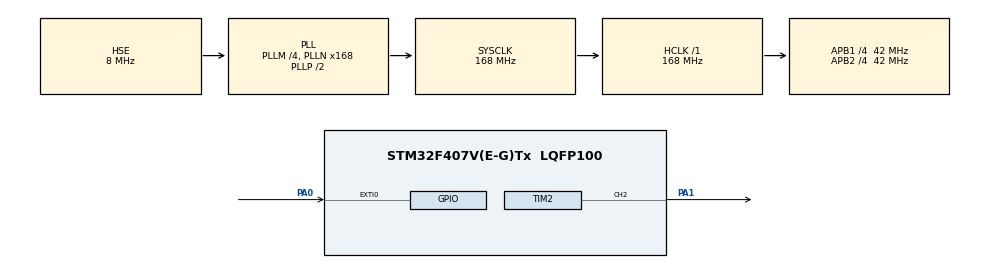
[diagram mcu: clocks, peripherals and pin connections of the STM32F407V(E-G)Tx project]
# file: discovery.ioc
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Mcu.Family=STM32F4
Mcu.Name=STM32F407V(E-G)Tx
Mcu.Package=LQFP100
NVIC.EXTI0_IRQn=true\:0\:0\:false\:false\:true\:true\:true\:true
NVIC.PriorityGroup=NVIC_PRIORITYGROUP_4
NVIC.TIM6_DAC_IRQn=true\:0\:0\:false\:false\:true\:true\:true\:true
PA0-WKUP.Signal=GPXTI0
PA1.Signal=S_TIM2_CH2
PH0-OSC_IN.Mode=HSE-External-Oscillator
PH0-OSC_IN.Signal=RCC_OSC_IN
PH1-OSC_OUT.Mode=HSE-External-Oscillator
PH1-OSC_OUT.Signal=RCC_OSC_OUT
ProjectManager.HeapSize=0x200
ProjectManager.StackSize=0x400
ProjectManager.TargetToolchain=STM32CubeIDE
RCC.48MHZClocksFreq_Value=84000000
RCC.AHBFreq_Value=168000000
RCC.APB1CLKDivider=RCC_HCLK_DIV4
RCC.APB1Freq_Value=42000000
RCC.APB1TimFreq_Value=84000000
RCC.APB2CLKDivider=RCC_HCLK_DIV4
RCC.APB2Freq_Value=42000000
RCC.APB2TimFreq_Value=84000000
RCC.CortexFreq_Value=168000000
RCC.HCLKFreq_Value=168000000
RCC.HSE_VALUE=8000000
RCC.HSI_VALUE=16000000
RCC.LSE_VALUE=32768
RCC.PLLM=4
RCC.PLLN=168
RCC.PLLSourceVirtual=RCC_PLLSOURCE_HSE
RCC.SYSCLKFreq_VALUE=168000000
RCC.SYSCLKSource=RCC_SYSCLKSOURCE_PLLCLK
RCC.VCOOutputFreq_Value=336000000
SH.S_TIM2_CH2.0=TIM2_CH2,PWM Generation2 CH2
TIM2.Channel-PWM\ Generation2\ CH2=TIM_CHANNEL_2
TIM2.Period=9999
TIM2.Prescaler=83
TIM6.AutoReloadPreload=TIM_AUTORELOAD_PRELOAD_ENABLE
TIM6.Period=999
TIM6.Prescaler=83
TIM6.TIM_MasterOutputTrigger=TIM_TRGO_UPDATE
VP_TIM2_VS_ClockSourceINT.Mode=Internal
VP_TIM6_VS_ClockSourceINT.Mode=Enable_Timer
board=custom

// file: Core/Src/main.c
/* USER CODE BEGIN Header */
/**
 ******************************************************************************
 * @file           : main.c
 * @brief          : Main program body
 ******************************************************************************
 * @attention
 *
 * Copyright (c) 2024 STMicroelectronics.
 * All rights reserved.
 *
 * This software is licensed under terms that can be found in the LICENSE file
 * in the root directory of this software component.
 * If no LICENSE file comes with this software, it is provided AS-IS.
 *
 ******************************************************************************
 */
/* USER CODE END Header */
#include "main.h"

/* USER CODE BEGIN Includes */
#include "stdio.h"
#include "string.h"
/* USER CODE END Includes */

TIM_HandleTypeDef htim2;
TIM_HandleTypeDef htim6;

/* USER CODE BEGIN PV */
#define USE_FULL_ASSERT 1
/* USER CODE END PV */

void SystemClock_Config(void);
static void MX_GPIO_Init(void);
static void MX_TIM6_Init(void);
static void MX_TIM2_Init(void);

/* USER CODE BEGIN 0 */
uint8_t counter = 0;
uint32_t tim_counter = 0;

typedef enum {
	INIT = 0, IDLE, BLE_COMMUNICATION, USER_VALID, LOG, LOCK_ERROR
} lock_states_t;

lock_states_t state = INIT;

typedef enum {
	OK = 0, ERR
} result_t;

result_t init(void);
result_t idle(void);
result_t ble_communication(lock_states_t *state);
result_t open_the_lock(void);
result_t error(void);
result_t log_to_flash(void);

/* USER CODE END 0 */

int main(void) {

	/* MCU Configuration--------------------------------------------------------*/

	/* Reset of all peripherals, Initializes the Flash interface and the Systick. */
	HAL_Init();

	/* Configure the system clock */
	SystemClock_Config();

	/* Initialize all configured peripherals */
	MX_GPIO_Init();
	MX_TIM6_Init();
	MX_TIM2_Init();
	/* USER CODE BEGIN 2 */
	HAL_TIM_Base_Start_IT(&htim6);

	HAL_TIM_PWM_Start(&htim2, TIM_CHANNEL_2);
	TIM2->CCR2 = 3333;
	/* USER CODE END 2 */

	/* Infinite loop */
	while (1) {

		/* USER CODE BEGIN 3 */
		switch (state) {

		case INIT:
			if (init() == OK) {
				state = IDLE;
			} else {
				state = LOCK_ERROR;
			}

			break;

		case IDLE:

			char x[3] = "";
			sprintf(x, "%d",5000000);

			idle();
			break;

		case BLE_COMMUNICATION:
			ble_communication(&state);
			break;
		case LOCK_ERROR:
			// show the error to the user
			state = LOG;
			break;

		case LOG:
			// log output to flash memory
			state = IDLE;
			break;

			// ...

		}
	}
	/* USER CODE END 3 */
}

void SystemClock_Config(void) {
	RCC_OscInitTypeDef RCC_OscInitStruct = { 0 };
	RCC_ClkInitTypeDef RCC_ClkInitStruct = { 0 };

	/** Configure the main internal regulator output voltage
	 */
	__HAL_RCC_PWR_CLK_ENABLE();
	__HAL_PWR_VOLTAGESCALING_CONFIG(PWR_REGULATOR_VOLTAGE_SCALE1);

	/** Initializes the RCC Oscillators according to the specified parameters
	 * in the RCC_OscInitTypeDef structure.
	 */
	RCC_OscInitStruct.OscillatorType = RCC_OSCILLATORTYPE_HSE;
	RCC_OscInitStruct.HSEState = RCC_HSE_ON;
	RCC_OscInitStruct.PLL.PLLState = RCC_PLL_ON;
	RCC_OscInitStruct.PLL.PLLSource = RCC_PLLSOURCE_HSE;
	RCC_OscInitStruct.PLL.PLLM = 4;
	RCC_OscInitStruct.PLL.PLLN = 168;
	RCC_OscInitStruct.PLL.PLLP = RCC_PLLP_DIV2;
	RCC_OscInitStruct.PLL.PLLQ = 4;
	if (HAL_RCC_OscConfig(&RCC_OscInitStruct) != HAL_OK) {
		Error_Handler();
	}

	/** Initializes the CPU, AHB and APB buses clocks
	 */
	RCC_ClkInitStruct.ClockType = RCC_CLOCKTYPE_HCLK | RCC_CLOCKTYPE_SYSCLK
			| RCC_CLOCKTYPE_PCLK1 | RCC_CLOCKTYPE_PCLK2;
	RCC_ClkInitStruct.SYSCLKSource = RCC_SYSCLKSOURCE_PLLCLK;
	RCC_ClkInitStruct.AHBCLKDivider = RCC_SYSCLK_DIV1;
	RCC_ClkInitStruct.APB1CLKDivider = RCC_HCLK_DIV4;
	RCC_ClkInitStruct.APB2CLKDivider = RCC_HCLK_DIV4;

	if (HAL_RCC_ClockConfig(&RCC_ClkInitStruct, FLASH_LATENCY_5) != HAL_OK) {
		Error_Handler();
	}
}

static void MX_TIM2_Init(void) {

	TIM_ClockConfigTypeDef sClockSourceConfig = { 0 };
	TIM_MasterConfigTypeDef sMasterConfig = { 0 };
	TIM_OC_InitTypeDef sConfigOC = { 0 };

	htim2.Instance = TIM2;
	htim2.Init.Prescaler = 83;
	htim2.Init.CounterMode = TIM_COUNTERMODE_UP;
	htim2.Init.Period = 9999;
	htim2.Init.ClockDivision = TIM_CLOCKDIVISION_DIV1;
	htim2.Init.AutoReloadPreload = TIM_AUTORELOAD_PRELOAD_DISABLE;
	if (HAL_TIM_Base_Init(&htim2) != HAL_OK) {
		Error_Handler();
	}
	sClockSourceConfig.ClockSource = TIM_CLOCKSOURCE_INTERNAL;
	if (HAL_TIM_ConfigClockSource(&htim2, &sClockSourceConfig) != HAL_OK) {
		Error_Handler();
	}
	if (HAL_TIM_PWM_Init(&htim2) != HAL_OK) {
		Error_Handler();
	}
	sMasterConfig.MasterOutputTrigger = TIM_TRGO_RESET;
	sMasterConfig.MasterSlaveMode = TIM_MASTERSLAVEMODE_DISABLE;
	if (HAL_TIMEx_MasterConfigSynchronization(&htim2, &sMasterConfig)
			!= HAL_OK) {
		Error_Handler();
	}
	sConfigOC.OCMode = TIM_OCMODE_PWM1;
	sConfigOC.Pulse = 0;
	sConfigOC.OCPolarity = TIM_OCPOLARITY_HIGH;
	sConfigOC.OCFastMode = TIM_OCFAST_DISABLE;
	if (HAL_TIM_PWM_ConfigChannel(&htim2, &sConfigOC, TIM_CHANNEL_2)
			!= HAL_OK) {
		Error_Handler();
	}
	HAL_TIM_MspPostInit(&htim2);

}

static void MX_TIM6_Init(void) {

	TIM_MasterConfigTypeDef sMasterConfig = { 0 };

	htim6.Instance = TIM6;
	htim6.Init.Prescaler = 83;
	htim6.Init.CounterMode = TIM_COUNTERMODE_UP;
	htim6.Init.Period = 999;
	htim6.Init.AutoReloadPreload = TIM_AUTORELOAD_PRELOAD_ENABLE;
	if (HAL_TIM_Base_Init(&htim6) != HAL_OK) {
		Error_Handler();
	}
	sMasterConfig.MasterOutputTrigger = TIM_TRGO_UPDATE;
	sMasterConfig.MasterSlaveMode = TIM_MASTERSLAVEMODE_DISABLE;
	if (HAL_TIMEx_MasterConfigSynchronization(&htim6, &sMasterConfig)
			!= HAL_OK) {
		Error_Handler();
	}

}

static void MX_GPIO_Init(void) {
	GPIO_InitTypeDef GPIO_InitStruct = { 0 };

	/* GPIO Ports Clock Enable */
	__HAL_RCC_GPIOH_CLK_ENABLE();
	__HAL_RCC_GPIOA_CLK_ENABLE();

	/*Configure GPIO pin : PA0 */
	GPIO_InitStruct.Pin = GPIO_PIN_0;
	GPIO_InitStruct.Mode = GPIO_MODE_IT_RISING;
	GPIO_InitStruct.Pull = GPIO_NOPULL;
	HAL_GPIO_Init(GPIOA, &GPIO_InitStruct);

	/* EXTI interrupt init*/
	HAL_NVIC_SetPriority(EXTI0_IRQn, 0, 0);
	HAL_NVIC_EnableIRQ(EXTI0_IRQn);

}

/* USER CODE BEGIN 4 */
void HAL_GPIO_EXTI_Callback(uint16_t GPIO_Pin) {

	if (state == IDLE) // and other conditions {
	{
		state = BLE_COMMUNICATION;
	}
}

void HAL_TIM_PeriodElapsedCallback(TIM_HandleTypeDef *htim) {

	if (htim->Instance == TIM6) {
		tim_counter++;
	}
}

result_t init(void) {
	return OK;
}
result_t idle(void) {
	return OK;
}
result_t ble_communication(lock_states_t *state) {

	// do the tasks here
	*state = USER_VALID;
	return OK;
}
result_t open_the_lock(void) {
	return OK;
}
result_t error(void) {
	return OK;
}
result_t log_to_flash(void) {
	return OK;
}

/* USER CODE END 4 */

void Error_Handler(void) {
	__disable_irq();
	while (1) {
	}
}
